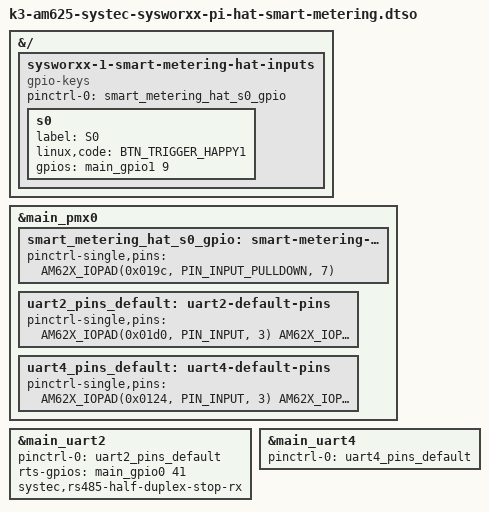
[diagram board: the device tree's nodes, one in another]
// SPDX-License-Identifier: GPL-2.0

/**
 * Copyright (C) 2025 SYS TEC electronic AG
 *
 * sysWORXX Pi HAT – Smart Metering
 */

/dts-v1/;
/plugin/;

#include <dt-bindings/gpio/gpio.h>
#include <dt-bindings/input/input.h>
#include "k3-pinctrl.h"

&{/} {
	sysworxx-1-smart-metering-hat-inputs {
		pinctrl-names = "default";
		pinctrl-0 = <&smart_metering_hat_s0_gpio>;
		compatible = "gpio-keys";

		s0 { label = "S0"; linux,code = <BTN_TRIGGER_HAPPY1>; gpios = <&main_gpio1 9 GPIO_ACTIVE_HIGH>; };
	};
};

&main_pmx0 {
	smart_metering_hat_s0_gpio: smart-metering-hat-s0-gpio {
		pinctrl-single,pins = <
			AM62X_IOPAD(0x019c, PIN_INPUT_PULLDOWN, 7) /* (B18) MCASP0_AXR1.GPIO1_9 */
		>;
	};

	uart2_pins_default: uart2-default-pins {
		pinctrl-single,pins = <
			AM62X_IOPAD(0x01d0, PIN_INPUT, 3) /* (A15) UART0_CTSn.UART2_RXD */
			AM62X_IOPAD(0x01d4, PIN_OUTPUT, 3) /* (B15) UART0_RTSn.UART2_TXD */
			// DEN
			AM62X_IOPAD(0x00a8, PIN_INPUT_PULLDOWN, 7) /* (M21) GPMC0_CSn0.GPIO0_41 */
		>;
	};

	uart4_pins_default: uart4-default-pins {
		pinctrl-single,pins = <
			AM62X_IOPAD(0x0124, PIN_INPUT, 3) /* (A23) MMC2_SDCD.UART4_RXD */
			AM62X_IOPAD(0x0128, PIN_OUTPUT, 3) /* (B23) MMC2_SDWP.UART4_TXD */
		>;
	};
};

// RS-485 / Modbus RTU
&main_uart2 {
	pinctrl-names = "default";
	pinctrl-0 = <&uart2_pins_default>;
	status = "okay";
	rts-gpios = <&main_gpio0 41 GPIO_ACTIVE_HIGH>;
	systec,rs485-half-duplex-stop-rx;
};

// M-Bus
&main_uart4 {
	pinctrl-names = "default";
	pinctrl-0 = <&uart4_pins_default>;
	status = "okay";
};
